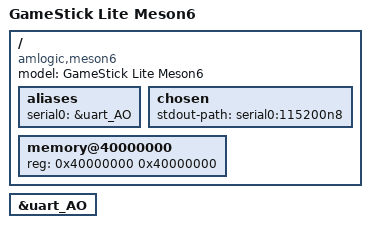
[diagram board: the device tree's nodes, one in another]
/dts-v1/;
#include "meson.dtsi"

/ {
	model = "GameStick Lite Meson6";
	compatible = "amlogic,meson6";

	aliases {
		serial0 = &uart_AO;
	};

	chosen {
		stdout-path = "serial0:115200n8";
	};

	memory@40000000 {
		device_type = "memory";
		reg = <0x40000000 0x40000000>; /* Assuming 1GB RAM */
	};
};

&uart_AO {
	status = "okay";
};
